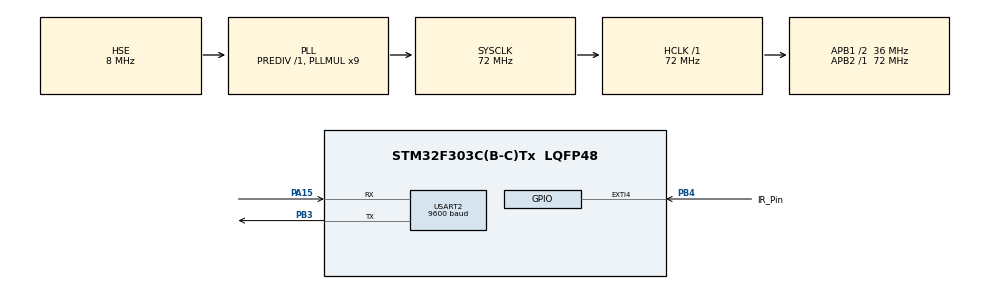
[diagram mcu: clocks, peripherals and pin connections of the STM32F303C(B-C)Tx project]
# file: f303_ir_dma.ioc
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Mcu.Family=STM32F3
RCC.PLLSourceVirtual=RCC_PLLSOURCE_HSE
PC15-OSC32_OUT.Mode=LSE-External-Oscillator
NVIC.EXTI4_IRQn=true\:0\:0\:false\:false\:true\:true\:true
RCC.CortexFreq_Value=72000000
PB4.GPIO_ModeDefaultEXTI=GPIO_MODE_IT_FALLING
RCC.SYSCLKSourceVirtual=RCC_SYSCLKSOURCE_PLLCLK
VP_RTC_VS_RTC_Activate.Mode=RTC_Enabled
RCC.APB1CLKDivider=RCC_HCLK_DIV2
PC14-OSC32_IN.Signal=RCC_OSC32_IN
USART2.BaudRate=9600
ProjectManager.StackSize=0x400
Dma.TIM4_UP.0.MemInc=DMA_MINC_ENABLE
PA13.Signal=SYS_JTMS-SWDIO
ProjectManager.TargetToolchain=STM32CubeIDE
Dma.TIM4_UP.0.PeriphInc=DMA_PINC_DISABLE
RCC.HCLKFreq_Value=72000000
RCC.APB2TimFreq_Value=72000000
RCC.USBFreq_Value=72000000
Dma.TIM4_UP.0.MemDataAlignment=DMA_MDATAALIGN_HALFWORD
TIM4.Prescaler=71
Dma.TIM4_UP.0.Direction=DMA_PERIPH_TO_MEMORY
PC15-OSC32_OUT.Signal=RCC_OSC32_OUT
RCC.AHBFreq_Value=72000000
PF0-OSC_IN.Mode=HSE-External-Oscillator
RCC.HSE_VALUE=8000000
PB3.Mode=Asynchronous
board=custom
USART2.VirtualMode-Asynchronous=VM_ASYNC
PA15.Mode=Asynchronous
RCC.RTCClockSelection=RCC_RTCCLKSOURCE_LSE
RCC.PLLMUL=RCC_PLL_MUL9
RCC.APB2Freq_Value=72000000
PC14-OSC32_IN.Mode=LSE-External-Oscillator
PB4.GPIO_Label=IR_Pin
Dma.TIM4_UP.0.Mode=DMA_CIRCULAR
PA14.Mode=Serial_Wire
Dma.TIM4_UP.0.PeriphDataAlignment=DMA_PDATAALIGN_HALFWORD
TIM4.Period=49
PA13.Mode=Serial_Wire
Mcu.Name=STM32F303C(B-C)Tx
PB3.Signal=USART2_TX
RCC.SYSCLKFreq_VALUE=72000000
Dma.TIM4_UP.0.Instance=DMA1_Channel7
Mcu.Package=LQFP48
Dma.TIM4_UP.0.Priority=DMA_PRIORITY_LOW
PA14.Signal=SYS_JTCK-SWCLK
VP_RTC_VS_RTC_Calendar.Mode=RTC_Calendar
PA15.Signal=USART2_RX
ProjectManager.HeapSize=0x200
RCC.HSI_VALUE=8000000
VP_TIM4_VS_ClockSourceINT.Mode=Internal
NVIC.PriorityGroup=NVIC_PRIORITYGROUP_4
RCC.APB1TimFreq_Value=72000000
NVIC.DMA1_Channel7_IRQn=true\:0\:0\:false\:false\:true\:false\:true
PF0-OSC_IN.Signal=RCC_OSC_IN
PF1-OSC_OUT.Mode=HSE-External-Oscillator
Dma.Request0=TIM4_UP
RCC.APB1Freq_Value=36000000
PF1-OSC_OUT.Signal=RCC_OSC_OUT
PB4.Signal=GPXTI4

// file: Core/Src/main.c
/* USER CODE BEGIN Header */
/**
 ******************************************************************************
 * @file           : main.c
 * @brief          : Main program body
 ******************************************************************************
 * @attention
 *
 * <h2><center>&copy; Copyright (c) 2021 STMicroelectronics.
 * All rights reserved.</center></h2>
 *
 * This software component is licensed by ST under BSD 3-Clause license,
 * the "License"; You may not use this file except in compliance with the
 * License. You may obtain a copy of the License at:
 *                        opensource.org/licenses/BSD-3-Clause
 *
 ******************************************************************************
 */
/* USER CODE END Header */
#include "main.h"

/* USER CODE BEGIN Includes */
#include "IRremote.h"
#include "stdio.h"
/* USER CODE END Includes */

/* USER CODE BEGIN PD */
#define IRBUFSIZE 2048
/* USER CODE END PD */

RTC_HandleTypeDef hrtc;

TIM_HandleTypeDef htim4;
DMA_HandleTypeDef hdma_tim4_up;

UART_HandleTypeDef huart2;

void SystemClock_Config(void);
static void MX_GPIO_Init(void);
static void MX_DMA_Init(void);
static void MX_RTC_Init(void);
static void MX_TIM4_Init(void);
static void MX_USART2_UART_Init(void);
/* USER CODE BEGIN PFP */
uint16_t ir_buffer[IRBUFSIZE];
/* USER CODE END PFP */

/* USER CODE BEGIN 0 */
void HAL_GPIO_EXTI_Callback(uint16_t GPIO_Pin)
{
	HAL_NVIC_DisableIRQ(EXTI4_IRQn);
	__HAL_TIM_ENABLE(&htim4);
}
void dma_cplt_callback(DMA_HandleTypeDef *hdma_instance)
{
	__HAL_TIM_DISABLE(&htim4);
	uint16_t i = 0, len;
	uint8_t trans_str[64];
	while (irparams.rcvstate != STATE_STOP)
	{
		ir_state_machine(((ir_buffer[i] & IR_Pin_Pin) == 0) ? 0 : 1);
		i++;
		if (i == IRBUFSIZE) break;
	}
	if (my_decode(&results))
	{
		len = snprintf((char*)trans_str, 64, "Code: HEX %p DEC %lu i %d\n", (void*) results.value, results.value, i);
		HAL_UART_Transmit(&huart2, trans_str, len, 1000);
	}
	my_resume();
	HAL_DMA_Start_IT(htim4.hdma[TIM_DMA_ID_UPDATE], (uint32_t) &IR_Pin_GPIO_Port->IDR, (uint32_t) &ir_buffer[1], IRBUFSIZE-1);
	__HAL_TIM_ENABLE_DMA(&htim4, TIM_DMA_UPDATE);
	HAL_NVIC_EnableIRQ(EXTI4_IRQn);
}
/* USER CODE END 0 */

int main(void)
{

	/* MCU Configuration--------------------------------------------------------*/

	/* Reset of all peripherals, Initializes the Flash interface and the Systick. */
	HAL_Init();

	/* Configure the system clock */
	SystemClock_Config();

	/* Initialize all configured peripherals */
	MX_GPIO_Init();
	MX_DMA_Init();
	MX_RTC_Init();
	MX_TIM4_Init();
	MX_USART2_UART_Init();
	/* USER CODE BEGIN 2 */
	my_enableIRIn();

	HAL_DMA_RegisterCallback(&hdma_tim4_up, HAL_DMA_XFER_CPLT_CB_ID, dma_cplt_callback);
	ir_buffer[0] = 0;
	HAL_DMA_Start_IT(htim4.hdma[TIM_DMA_ID_UPDATE], (uint32_t) &IR_Pin_GPIO_Port->IDR, (uint32_t) &ir_buffer[1], IRBUFSIZE-1);
	__HAL_TIM_ENABLE_DMA(&htim4, TIM_DMA_UPDATE);

	/* USER CODE END 2 */

	/* Infinite loop */
	while (1)
	{

	}
}

void SystemClock_Config(void)
{
	RCC_OscInitTypeDef RCC_OscInitStruct = { 0 };
	RCC_ClkInitTypeDef RCC_ClkInitStruct = { 0 };
	RCC_PeriphCLKInitTypeDef PeriphClkInit = { 0 };

	/** Configure LSE Drive Capability
	 */
	HAL_PWR_EnableBkUpAccess();
	__HAL_RCC_LSEDRIVE_CONFIG(RCC_LSEDRIVE_LOW);
	/** Initializes the RCC Oscillators according to the specified parameters
	 * in the RCC_OscInitTypeDef structure.
	 */
	RCC_OscInitStruct.OscillatorType = RCC_OSCILLATORTYPE_HSE | RCC_OSCILLATORTYPE_LSE;
	RCC_OscInitStruct.HSEState = RCC_HSE_ON;
	RCC_OscInitStruct.HSEPredivValue = RCC_HSE_PREDIV_DIV1;
	RCC_OscInitStruct.LSEState = RCC_LSE_ON;
	RCC_OscInitStruct.HSIState = RCC_HSI_ON;
	RCC_OscInitStruct.PLL.PLLState = RCC_PLL_ON;
	RCC_OscInitStruct.PLL.PLLSource = RCC_PLLSOURCE_HSE;
	RCC_OscInitStruct.PLL.PLLMUL = RCC_PLL_MUL9;
	if (HAL_RCC_OscConfig(&RCC_OscInitStruct) != HAL_OK)
	{
		Error_Handler();
	}
	/** Initializes the CPU, AHB and APB buses clocks
	 */
	RCC_ClkInitStruct.ClockType = RCC_CLOCKTYPE_HCLK | RCC_CLOCKTYPE_SYSCLK | RCC_CLOCKTYPE_PCLK1 | RCC_CLOCKTYPE_PCLK2;
	RCC_ClkInitStruct.SYSCLKSource = RCC_SYSCLKSOURCE_PLLCLK;
	RCC_ClkInitStruct.AHBCLKDivider = RCC_SYSCLK_DIV1;
	RCC_ClkInitStruct.APB1CLKDivider = RCC_HCLK_DIV2;
	RCC_ClkInitStruct.APB2CLKDivider = RCC_HCLK_DIV1;

	if (HAL_RCC_ClockConfig(&RCC_ClkInitStruct, FLASH_LATENCY_2) != HAL_OK)
	{
		Error_Handler();
	}
	PeriphClkInit.PeriphClockSelection = RCC_PERIPHCLK_USART2 | RCC_PERIPHCLK_RTC;
	PeriphClkInit.Usart2ClockSelection = RCC_USART2CLKSOURCE_PCLK1;
	PeriphClkInit.RTCClockSelection = RCC_RTCCLKSOURCE_LSE;
	if (HAL_RCCEx_PeriphCLKConfig(&PeriphClkInit) != HAL_OK)
	{
		Error_Handler();
	}
}

static void MX_RTC_Init(void)
{

	RTC_TimeTypeDef sTime = { 0 };
	RTC_DateTypeDef sDate = { 0 };

	/** Initialize RTC Only
	 */
	hrtc.Instance = RTC;
	hrtc.Init.HourFormat = RTC_HOURFORMAT_24;
	hrtc.Init.AsynchPrediv = 127;
	hrtc.Init.SynchPrediv = 255;
	hrtc.Init.OutPut = RTC_OUTPUT_DISABLE;
	hrtc.Init.OutPutPolarity = RTC_OUTPUT_POLARITY_HIGH;
	hrtc.Init.OutPutType = RTC_OUTPUT_TYPE_OPENDRAIN;
	if (HAL_RTC_Init(&hrtc) != HAL_OK)
	{
		Error_Handler();
	}

	/** Initialize RTC and set the Time and Date
	 */
	sTime.Hours = 0x0;
	sTime.Minutes = 0x0;
	sTime.Seconds = 0x0;
	sTime.DayLightSaving = RTC_DAYLIGHTSAVING_NONE;
	sTime.StoreOperation = RTC_STOREOPERATION_RESET;
	if (HAL_RTC_SetTime(&hrtc, &sTime, RTC_FORMAT_BCD) != HAL_OK)
	{
		Error_Handler();
	}
	sDate.WeekDay = RTC_WEEKDAY_MONDAY;
	sDate.Month = RTC_MONTH_JANUARY;
	sDate.Date = 0x1;
	sDate.Year = 0x0;

	if (HAL_RTC_SetDate(&hrtc, &sDate, RTC_FORMAT_BCD) != HAL_OK)
	{
		Error_Handler();
	}

}

static void MX_TIM4_Init(void)
{

	TIM_ClockConfigTypeDef sClockSourceConfig = { 0 };
	TIM_MasterConfigTypeDef sMasterConfig = { 0 };

	htim4.Instance = TIM4;
	htim4.Init.Prescaler = 71;
	htim4.Init.CounterMode = TIM_COUNTERMODE_UP;
	htim4.Init.Period = 49;
	htim4.Init.ClockDivision = TIM_CLOCKDIVISION_DIV1;
	htim4.Init.AutoReloadPreload = TIM_AUTORELOAD_PRELOAD_DISABLE;
	if (HAL_TIM_Base_Init(&htim4) != HAL_OK)
	{
		Error_Handler();
	}
	sClockSourceConfig.ClockSource = TIM_CLOCKSOURCE_INTERNAL;
	if (HAL_TIM_ConfigClockSource(&htim4, &sClockSourceConfig) != HAL_OK)
	{
		Error_Handler();
	}
	sMasterConfig.MasterOutputTrigger = TIM_TRGO_RESET;
	sMasterConfig.MasterSlaveMode = TIM_MASTERSLAVEMODE_DISABLE;
	if (HAL_TIMEx_MasterConfigSynchronization(&htim4, &sMasterConfig) != HAL_OK)
	{
		Error_Handler();
	}

}

static void MX_USART2_UART_Init(void)
{

	huart2.Instance = USART2;
	huart2.Init.BaudRate = 9600;
	huart2.Init.WordLength = UART_WORDLENGTH_8B;
	huart2.Init.StopBits = UART_STOPBITS_1;
	huart2.Init.Parity = UART_PARITY_NONE;
	huart2.Init.Mode = UART_MODE_TX_RX;
	huart2.Init.HwFlowCtl = UART_HWCONTROL_NONE;
	huart2.Init.OverSampling = UART_OVERSAMPLING_16;
	huart2.Init.OneBitSampling = UART_ONE_BIT_SAMPLE_DISABLE;
	huart2.AdvancedInit.AdvFeatureInit = UART_ADVFEATURE_NO_INIT;
	if (HAL_UART_Init(&huart2) != HAL_OK)
	{
		Error_Handler();
	}

}

static void MX_DMA_Init(void)
{

	/* DMA controller clock enable */
	__HAL_RCC_DMA1_CLK_ENABLE();

	/* DMA interrupt init */
	/* DMA1_Channel7_IRQn interrupt configuration */
	HAL_NVIC_SetPriority(DMA1_Channel7_IRQn, 0, 0);
	HAL_NVIC_EnableIRQ(DMA1_Channel7_IRQn);

}

static void MX_GPIO_Init(void)
{
	GPIO_InitTypeDef GPIO_InitStruct = { 0 };

	/* GPIO Ports Clock Enable */
	__HAL_RCC_GPIOC_CLK_ENABLE();
	__HAL_RCC_GPIOF_CLK_ENABLE();
	__HAL_RCC_GPIOA_CLK_ENABLE();
	__HAL_RCC_GPIOB_CLK_ENABLE();

	/*Configure GPIO pin : IR_Pin_Pin */
	GPIO_InitStruct.Pin = IR_Pin_Pin;
	GPIO_InitStruct.Mode = GPIO_MODE_IT_FALLING;
	GPIO_InitStruct.Pull = GPIO_NOPULL;
	HAL_GPIO_Init(IR_Pin_GPIO_Port, &GPIO_InitStruct);

	/* EXTI interrupt init*/
	HAL_NVIC_SetPriority(EXTI4_IRQn, 0, 0);
	HAL_NVIC_EnableIRQ(EXTI4_IRQn);

}

void Error_Handler(void)
{
	__disable_irq();
	while (1)
	{
	}
}

/************************ (C) COPYRIGHT STMicroelectronics *****END OF FILE****/
